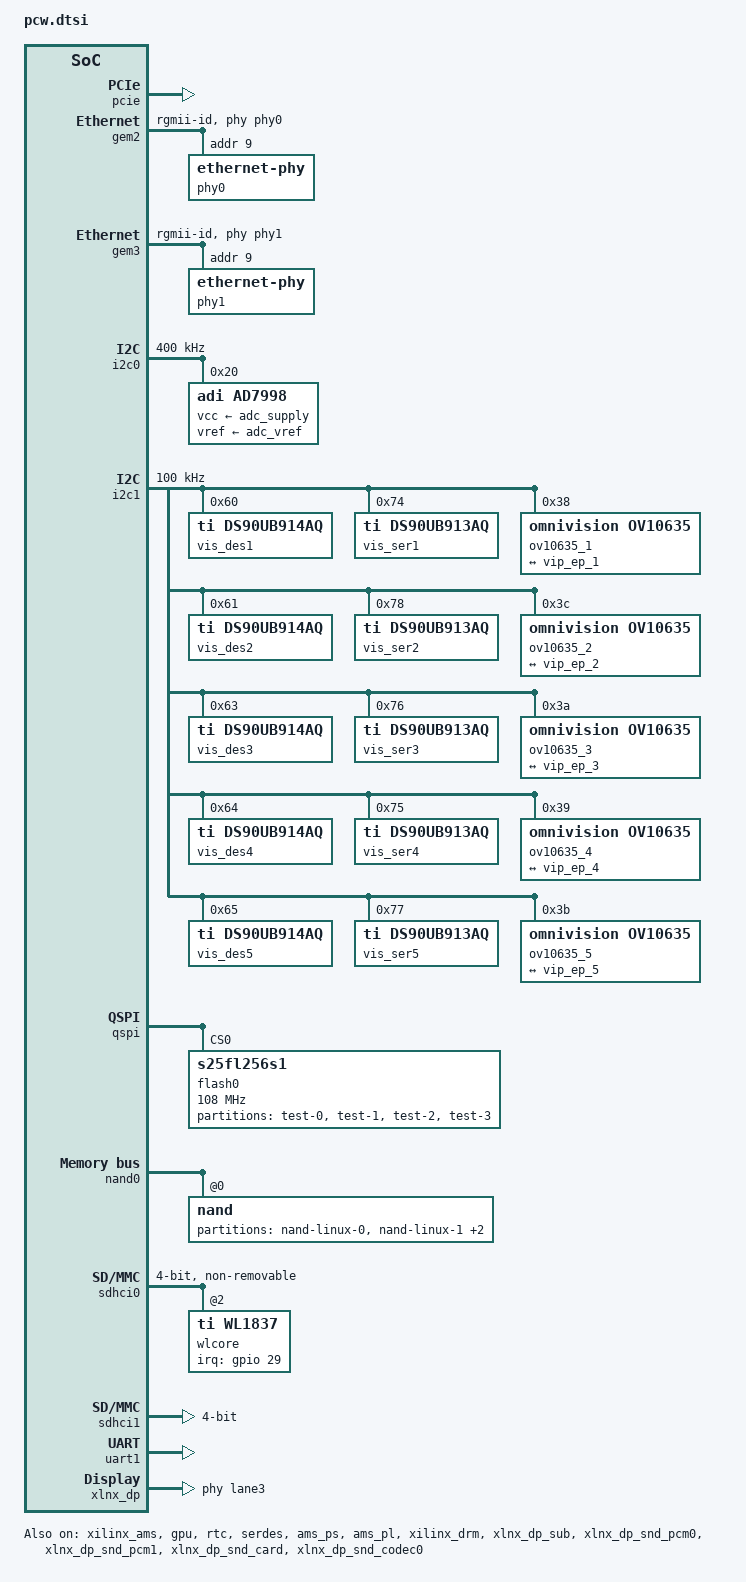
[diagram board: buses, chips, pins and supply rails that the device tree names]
/*
 * CAUTION: This file is automatically generated by Xilinx.
 * Version:  
 * Today is: Wed Nov  8 10:41:27 2017
 */

&lpd_dma_chan1 {
	status = "okay";
};
&lpd_dma_chan2 {
	status = "okay";
};
&lpd_dma_chan3 {
	status = "okay";
};
&lpd_dma_chan4 {
	status = "okay";
};
&lpd_dma_chan5 {
	status = "okay";
};
&lpd_dma_chan6 {
	status = "okay";
};
&lpd_dma_chan7 {
	status = "okay";
};
&lpd_dma_chan8 {
	status = "okay";
};
&xilinx_ams {
	status = "okay";
};
&fpd_dma_chan1 {
	status = "okay";
};
&fpd_dma_chan2 {
	status = "okay";
};
&fpd_dma_chan3 {
	status = "okay";
};
&fpd_dma_chan4 {
	status = "okay";
};
&fpd_dma_chan5 {
	status = "okay";
};
&fpd_dma_chan6 {
	status = "okay";
};
&fpd_dma_chan7 {
	status = "okay";
};
&fpd_dma_chan8 {
	status = "okay";
};

&gpio {
	emio-gpio-width = <32>;
	gpio-mask-high = <0x0>;
	gpio-mask-low = <0x5600>;
	status = "okay";
};

&gpu {
	status = "okay";
};

&smmu {
	status = "okay";
};

&pcie {
	status = "okay";
	xlnx,pcie-mode = "Root Port";
};

&gem2 {
	status = "okay";
	phy-handle = <&phy0>;
	phy-mode = "rgmii-id";
	phy-reset-gpio = <&gpio 10 1>;
	phy-reset-duration = <2>;
	phy-reset-active-low = <1>;
	local-mac-address = [00 0a 35 00 00 00];
	
	phy0: ethernet-phy@9 {
		reg = <0x9>;
		ti,rx-internal-delay = <0x8>;
		ti,tx-internal-delay = <0xa>;
		ti,fifo-depth = <0x1>;
		ti,rxctrl-strap-worka;
	};
};

&gem3 {
	status = "okay";
	phy-handle = <&phy1>;
	phy-mode = "rgmii-id";
	phy-reset-gpio = <&gpio 11 1>;
	phy-reset-duration = <2>;
	phy-reset-active-low = <1>;
	local-mac-address = [00 0a 35 00 00 01];
	
	phy1: ethernet-phy@9 {
		reg = <0x9>;
		ti,rx-internal-delay = <0x8>;
		ti,tx-internal-delay = <0xa>;
		ti,fifo-depth = <0x1>;
		ti,rxctrl-strap-worka;
	};
};

&i2c0 {
	clock-frequency = <400000>;
	status = "okay";
	
	ad7998@20 {
		compatible = "adi,ad7998";
		reg = <0x20>;
		vcc-supply = <&adc_supply>;
		vref-supply = <&adc_vref>;
	};
};

&i2c1 {
	clock-frequency = <100000>;
	status = "okay";
	
	vis_des1: ds90ub914aq@60 {
		compatible = "ti,ds90ub914aq";
		reg = <0x60>;
	};

	vis_ser1: ds90ub913aq@74 {
		compatible = "ti,ds90ub913aq";
		reg = <0x74>;
	};
	
	ov10635_1: ov10635@38 {
		compatible = "omnivision,ov10635";
		reg = <0x38>;
		deserializer = <&vis_des1>;
		serializer = <&vis_ser1>;

		port {
		      ov10635_ep_1: endpoint {
			      remote-endpoint = <&vip_ep_1>;      
		      };
		};
	};
	
	vis_des2: ds90ub914aq@61 {
		compatible = "ti,ds90ub914aq";
		reg = <0x61>;
	};

	vis_ser2: ds90ub913aq@78 {
		compatible = "ti,ds90ub913aq";
		reg = <0x78>;
	};
	
	ov10635_2: ov10635@3C {
		compatible = "omnivision,ov10635";
		reg = <0x3C>;
		deserializer = <&vis_des2>;
		serializer = <&vis_ser2>;

		port {
		      ov10635_ep_2: endpoint {
			      remote-endpoint = <&vip_ep_2>;      
		      };
		};
	};
	
	
	vis_des3: ds90ub914aq@63 {
		compatible = "ti,ds90ub914aq";
		reg = <0x63>;
	};

	vis_ser3: ds90ub913aq@76 {
		compatible = "ti,ds90ub913aq";
		reg = <0x76>;
	};
	
	ov10635_3: ov10635@3A {
		compatible = "omnivision,ov10635";
		reg = <0x3A>;
		deserializer = <&vis_des3>;
		serializer = <&vis_ser3>;

		port {
		      ov10635_ep_3: endpoint {
			      remote-endpoint = <&vip_ep_3>;      
		      };
		};
	};
	
	
	vis_des4: ds90ub914aq@64 {
		compatible = "ti,ds90ub914aq";
		reg = <0x64>;
	};

	vis_ser4: ds90ub913aq@75 {
		compatible = "ti,ds90ub913aq";
		reg = <0x75>;
	};
	
	ov10635_4: ov10635@39 {
		compatible = "omnivision,ov10635";
		reg = <0x39>;
		deserializer = <&vis_des4>;
		serializer = <&vis_ser4>;

		port {
		      ov10635_ep_4: endpoint {
			      remote-endpoint = <&vip_ep_4>;      
		      };
		};
	};
	
	
	vis_des5: ds90ub914aq@65 {
		compatible = "ti,ds90ub914aq";
		reg = <0x65>;
	};

	vis_ser5: ds90ub913aq@77 {
		compatible = "ti,ds90ub913aq";
		reg = <0x77>;
	};
	
	ov10635_5: ov10635@3B {
		compatible = "omnivision,ov10635";
		reg = <0x3B>;
		deserializer = <&vis_des5>;
		serializer = <&vis_ser5>;

		port {
		      ov10635_ep_5: endpoint {
			      remote-endpoint = <&vip_ep_5>;      
		      };
		};
	};
};

&pinctrl0 {
	status = "okay";
};

&qspi {
	is-dual = <0>;
	num-cs = <1>;
	status = "okay";
	has-io-mode;
	
	flash0: flash@0 {
		compatible = "s25fl256s1";
		spi-tx-bus-width=<1>;
		spi-rx-bus-width=<4>;
		reg = <0x0>;
		#address-cells = <1>;
		#size-cells = <1>;
		spi-max-frequency = <108000000>;
		
		partition@test-0 { /* test purposes */
			label = "test-0";
			reg = <0x00000000 0x00400000>;
		};
		partition@test-1 { /* test purposes */
			label = "test-1";
			reg = <0x00800000 0x00400000>;
		};
		partition@test-2 { /* test purposes */
			label = "test-2";
			reg = <0x01000000 0x00400000>;
		};
		partition@test-3 { /* test purposes */
			label = "test-3";
			reg = <0x01800000 0x00400000>;
		};
	};
};

&nand0 {
	status = "okay";
	arasan,has-mdma;
	num-cs = <1>;
	
	nand@0 {
		reg = <0x0>;
		#address-cells = <0x1>;
		#size-cells = <0x1>;
		
		partition@nand-linux-0 { /* test purposes */
			label = "nand-linux-0";
			reg = <0x00000000 0x02000000>;
		};
		partition@nand-linux-1 { /* test purposes */
			label = "nand-linux-1";
			reg = <0x04000000 0x02000000>;
		};
		partition@nand-linux-2 { /* test purposes */
			label = "nand-linux-2";
			reg = <0x08000000 0x02000000>;
		};
		partition@nand-linux-3 { /* test purposes */
			label = "nand-linux-3";
			reg = <0x0C000000 0x02000000>;
		};
	};
};

&rtc {
	status = "okay";
};

/*&sata {
	status = "okay";
	
	phy-names = "sata-phy";
	phys = <&lane1 1 1 1 150000000>;
	
	ceva,p0-cominit-params = /bits/ 8 <0x1B 0x4D 0x18 0x28>;
	ceva,p0-comwake-params = /bits/ 8 <0x06 0x19 0x08 0x0E>;
	ceva,p0-burst-params = /bits/ 8 <0x13 0x08 0x4A 0x06>;
	ceva,p0-retry-params = /bits/ 16 <0x96A4 0x3FFC>;
	ceva,p1-cominit-params = /bits/ 8 <0x1B 0x4D 0x18 0x28>;
	ceva,p1-comwake-params = /bits/ 8 <0x06 0x19 0x08 0x0E>;
	ceva,p1-burst-params = /bits/ 8 <0x13 0x08 0x4A 0x06>;
	ceva,p1-retry-params = /bits/ 16 <0x96A4 0x3FFC>;
	
	ceva,broken-gen2;
	dma-coherent;
};*/

&sdhci0 {
	clock-frequency = <50000000>;
	status = "okay";
	xlnx,mio_bank = <0x1>;
	
	non-removable;
	disable-wp;
	bus-width = <4>;
	
	//vmmc-supply = <&wlan_en>;
	max-frequency = <50000000>;
	
	cap-power-off-card;
	keep-power-in-suspend;
	
	#address-cells = <1>;
	#size-cells = <0>;
	wlcore: wlcore@2 {
		compatible = "ti,wl1837";
		reg = <2>;
		
		/* MIO 29 is IRQ now */
		interrupt-parent = <&gpio>;
		interrupts = <29 4>;
	};
};

&sdhci1 {
	clock-frequency = <0x5f5e100>;
	status = "okay";
	xlnx,mio_bank = <0x1>;
	no-1-8-v;
	disable-wp;
	bus-width = <4>;
};

&serdes {
	status = "okay";
};

&uart1 {
	device_type = "serial";
	port-number = <0>;
	status = "okay";
	u-boot,dm-pre-reloc ;
};

&pss_ref_clk {
	clock-frequency = <50000000>;
};

&ams_ps {
	status = "okay";
};

&ams_pl {
	status = "okay";
};

&xlnx_dp {
	phy-names = "dp-phy0","dp-phy1";
	phys = <&lane3 5 0 2 135000000>,
		<&lane2 5 1 2 135000000>;
	status = "okay";
	xlnx,max-lanes = <2>;
};

&xlnx_dpdma {
	status = "okay";
};

&xilinx_drm {
	status = "okay";
	
	/* TRD */
	planes {
		xlnx,pixel-format = "argb8888";
	};
};

&xlnx_dp_sub {
	status = "okay";
	
	/* TRD */
	xlnx,gfx-fmt = "argb8888";
};

&xlnx_dp_snd_pcm0 {
	status = "okay";
};

&xlnx_dp_snd_pcm1 {
	status = "okay";
};

&xlnx_dp_snd_card {
	status = "okay";
};

&xlnx_dp_snd_codec0 {
	status = "okay";
};
